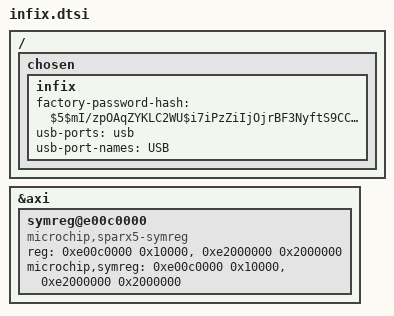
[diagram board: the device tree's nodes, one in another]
// SPDX-License-Identifier: GPL-2.0
/*
 * Common Infix OS defaults
 */

/ {
	chosen {
		infix {
			/* Default admin user password: 'admin' */
			factory-password-hash = "$5$mI/zpOAqZYKLC2WU$i7iPzZiIjOjrBF3NyftS9CCq8dfYwHwrmUK097Jca9A";
			usb-ports = <&usb>;
			usb-port-names = "USB";
		};
	};
};

/* Register access by name for the symreg tool, debugfs only */
&axi {
	symreg@e00c0000 {
		compatible = "microchip,sparx5-symreg";
		reg = <0xe00c0000 0x10000>,
		      <0xe2000000 0x2000000>;
		reg-names = "cpu", "dev";
		microchip,symreg = <0xe00c0000 0x10000>,
				   <0xe2000000 0x2000000>;
	};
};
